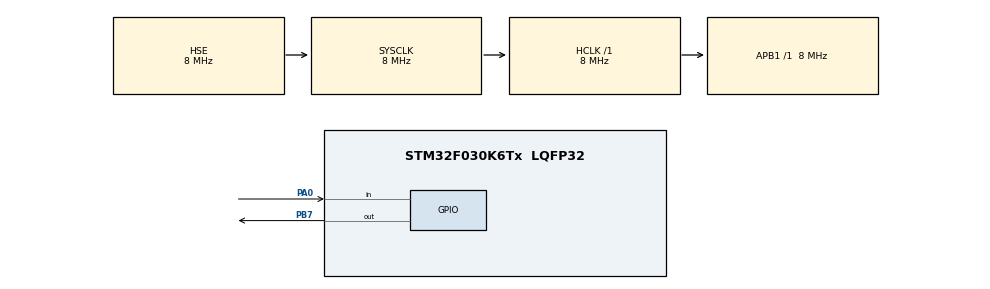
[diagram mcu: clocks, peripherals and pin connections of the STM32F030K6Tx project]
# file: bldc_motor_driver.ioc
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Mcu.Family=STM32F0
Mcu.Name=STM32F030K6Tx
Mcu.Package=LQFP32
PA0.GPIO_PuPd=GPIO_PULLUP
PA0.Signal=GPIO_Input
PA13.Mode=Serial_Wire
PA13.Signal=SYS_SWDIO
PA14.Mode=Serial_Wire
PA14.Signal=SYS_SWCLK
PB7.Signal=GPIO_Output
PF0-OSC_IN.Mode=HSE-External-Oscillator
PF0-OSC_IN.Signal=RCC_OSC_IN
PF1-OSC_OUT.Mode=HSE-External-Oscillator
PF1-OSC_OUT.Signal=RCC_OSC_OUT
ProjectManager.HeapSize=0x200
ProjectManager.StackSize=0x400
ProjectManager.TargetToolchain=Makefile
RCC.AHBFreq_Value=8000000
RCC.APB1Freq_Value=8000000
RCC.APB1TimFreq_Value=8000000
RCC.HCLKFreq_Value=8000000
RCC.PLLSourceVirtual=RCC_PLLSOURCE_HSE
RCC.SYSCLKFreq_VALUE=8000000
RCC.SYSCLKSource=RCC_SYSCLKSOURCE_HSE
board=custom

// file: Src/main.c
/* USER CODE BEGIN Header */
/**
  ******************************************************************************
  * @file           : main.c
  * @brief          : Main program body
  ******************************************************************************
  * @attention
  *
  * <h2><center>&copy; Copyright (c) 2019 STMicroelectronics.
  * All rights reserved.</center></h2>
  *
  * This software component is licensed by ST under BSD 3-Clause license,
  * the "License"; You may not use this file except in compliance with the
  * License. You may obtain a copy of the License at:
  *                        opensource.org/licenses/BSD-3-Clause
  *
  ******************************************************************************
  */
/* USER CODE END Header */

#include "main.h"

/* USER CODE BEGIN Includes */
#include "digital_input.h"
#include "pwm_output.h"
#include "pin_configuration.h"
/* USER CODE END Includes */

/* USER CODE BEGIN PV */

static digitalInput_handle_S buttonInput;
static pwmBase_handle_S pwmBase;
static pwmOutput_handle_S ledPwmOutput;

/* USER CODE END PV */

void SystemClock_Config(void);
static void MX_GPIO_Init(void);

int main(void)
{

  /* MCU Configuration--------------------------------------------------------*/

  /* Reset of all peripherals, Initializes the Flash interface and the Systick. */
  HAL_Init();

  /* Configure the system clock */
  SystemClock_Config();

  /* Initialize all configured peripherals */
  MX_GPIO_Init();
  /* USER CODE BEGIN 2 */

  pinConfiguration_setup();

  // SETUP BUTTON INPUT
  const digitalInput_config_S buttonInputConfig = {
    .GPIOx = GPIOA,
    .pin = GPIO_PIN_0,
    .pull = DIGITAL_INPUT_PULL_UP,
  };
  digitalInput_init(&buttonInput, buttonInputConfig);

  // SETUP PWM BASE
  const pwmBase_config_S pwmBaseConfig = {
    .timer = TIM17,
    .frequencyHz = 20U * KILO,
    .deadTimeNS = 0U,
  };
  pwmBase_init(&pwmBase, pwmBaseConfig);

  // SETUP LED PWM
  const pwmOutput_config_S ledPwmOutputConfig = {
    .timerOutputChannel = TIM_CHANNEL_1,
  };
  pwmOutput_init(&ledPwmOutput, ledPwmOutputConfig, &pwmBase);

  /* USER CODE END 2 */
  /* Infinite loop */
  /* USER CODE BEGIN WHILE */
  uint32_t count = 0U;
  bool rampingUp = TRUE;
  while (digitalInput_getState(&buttonInput))
  {
    pwmOutput_setDuty(&ledPwmOutput, _P15(1.0F) - (count * _P15(0.001)));
    if (rampingUp)
    {
      count++;
      if (count == 500U)
      {
        rampingUp = FALSE;
      }
    }
    else
    {
      count--;
      if (count == 0U)
      {
        rampingUp = TRUE;
      }
    }
    HAL_Delay(1U);
  }
  while (1)
  {
    const bool buttonState = digitalInput_getState(&buttonInput);
    if (buttonState)
    {
      pwmOutput_setDuty(&ledPwmOutput, _P15(1.0F));
    }
    else
    {
      pwmOutput_setDuty(&ledPwmOutput, _P15(0.9));
    }
    HAL_Delay(10U);
  }
  /* USER CODE END 3 */
}

void SystemClock_Config(void)
{
  RCC_OscInitTypeDef RCC_OscInitStruct = {0};
  RCC_ClkInitTypeDef RCC_ClkInitStruct = {0};

  /** Initializes the CPU, AHB and APB busses clocks
  */
  RCC_OscInitStruct.OscillatorType = RCC_OSCILLATORTYPE_HSE;
  RCC_OscInitStruct.HSEState = RCC_HSE_ON;
  RCC_OscInitStruct.PLL.PLLState = RCC_PLL_NONE;
  if (HAL_RCC_OscConfig(&RCC_OscInitStruct) != HAL_OK)
  {
    Error_Handler();
  }
  /** Initializes the CPU, AHB and APB busses clocks
  */
  RCC_ClkInitStruct.ClockType = RCC_CLOCKTYPE_HCLK|RCC_CLOCKTYPE_SYSCLK
                              |RCC_CLOCKTYPE_PCLK1;
  RCC_ClkInitStruct.SYSCLKSource = RCC_SYSCLKSOURCE_HSE;
  RCC_ClkInitStruct.AHBCLKDivider = RCC_SYSCLK_DIV1;
  RCC_ClkInitStruct.APB1CLKDivider = RCC_HCLK_DIV1;

  if (HAL_RCC_ClockConfig(&RCC_ClkInitStruct, FLASH_LATENCY_0) != HAL_OK)
  {
    Error_Handler();
  }
}

static void MX_GPIO_Init(void)
{
  /* GPIO Ports Clock Enable */
  __HAL_RCC_GPIOF_CLK_ENABLE();
  __HAL_RCC_GPIOA_CLK_ENABLE();
  __HAL_RCC_GPIOB_CLK_ENABLE();
}

void Error_Handler(void)
{
}

/************************ (C) COPYRIGHT STMicroelectronics *****END OF FILE****/
